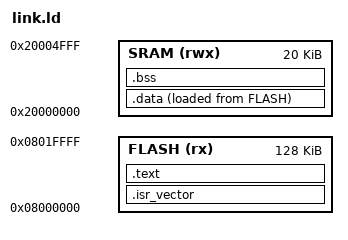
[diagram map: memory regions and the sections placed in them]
/* Minimal STM32F103 layout — matches the asset-generated Renode platform. */
ENTRY(Reset_Handler)
MEMORY
{
  FLASH (rx) : ORIGIN = 0x08000000, LENGTH = 128K
  SRAM (rwx) : ORIGIN = 0x20000000, LENGTH = 20K
}

_estack = ORIGIN(SRAM) + LENGTH(SRAM);

SECTIONS
{
  .isr_vector : { KEEP(*(.isr_vector)) } > FLASH
  .text : { *(.text*) *(.rodata*) } > FLASH
  .data : { *(.data*) } > SRAM AT > FLASH
  .bss  : { *(.bss*) } > SRAM
}
